# SA3_SS0_SA_UL_0_ECC_AGGR register map
Vendor: Texas Instruments
Peripheral module from a debugger description file (folder am62P).
Registers are 32-bit, access not given, reset 0x0 unless marked. A register's access mark holds for its fields unless they carry their own. Offsets are as the file gives them; lines under a group give offsets from that group; [hi:lo] are bit positions; {n}, {i} and the like mark numbered series; 'fields as' and 'values as' point back to an identical list; <NAME> marks a mode.

## SA3_SS0_SA_UL_0_ECC_AGGR
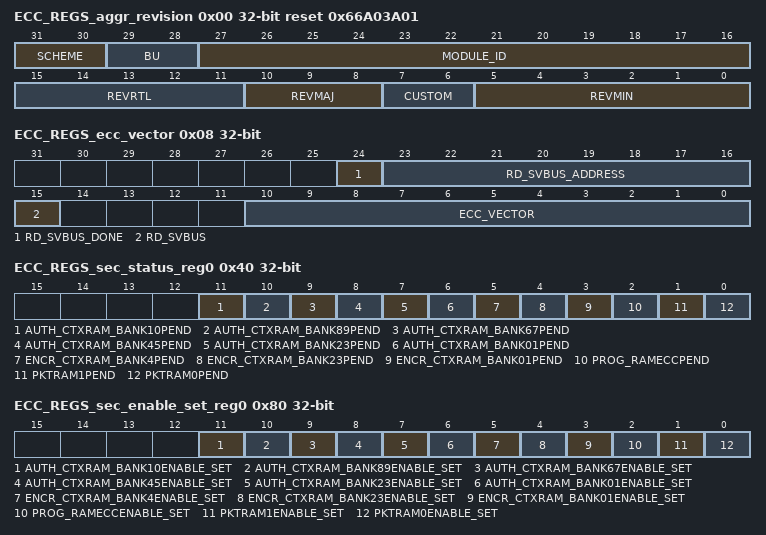
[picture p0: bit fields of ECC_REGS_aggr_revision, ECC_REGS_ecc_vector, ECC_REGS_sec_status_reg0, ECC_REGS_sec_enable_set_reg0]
0x00 ECC_REGS_aggr_revision ro reset 0x66A03A01 — Revision parameters
  [31:30] SCHEME
  [29:28] BU
  [27:16] MODULE_ID
  [15:11] REVRTL — RTL version
  [10:8] REVMAJ — Major version
  [7:6] CUSTOM — Custom version
  [5:0] REVMIN — Minor version
0x08 ECC_REGS_ecc_vector — ECC Vector Register
  [24] RD_SVBUS_DONE — Status to indicate if read on serial VBUS is complete, write of any value will clear this bit. (access R/W1TC)
  [23:16] RD_SVBUS_ADDRESS rw — Read address
  [15] RD_SVBUS — Write 1 to trigger a read on the serial VBUS (access R/W1TS)
  [10:0] ECC_VECTOR rw — Value written to select the corresponding ECC RAM for control or status
0x0C ECC_REGS_misc_status ro reset 0xC — Misc Status
  [10:0] NUM_RAMS — Indicates the number of RAMS serviced by the ECC aggregator
0x10 ECC_REGS_reserved_svbus rw — Reference other documents that contain the ECC RAM wrapper and EDC controller serial vbus register sets.
  [31:0] DATA — Serial VBUS register data
0x3C ECC_REGS_sec_eoi_reg — EOI Register
  [0] EOI_WR — EOI Register (access R/W1TS)
0x40 ECC_REGS_sec_status_reg0 — Interrupt Status Register 0
  [11] AUTH_CTXRAM_BANK10PEND — Interrupt Pending Status for auth_ctxram_bank10pend (access R/W1TS)
  [10] AUTH_CTXRAM_BANK89PEND — Interrupt Pending Status for auth_ctxram_bank89pend (access R/W1TS)
  [9] AUTH_CTXRAM_BANK67PEND — Interrupt Pending Status for auth_ctxram_bank67pend (access R/W1TS)
  [8] AUTH_CTXRAM_BANK45PEND — Interrupt Pending Status for auth_ctxram_bank45pend (access R/W1TS)
  [7] AUTH_CTXRAM_BANK23PEND — Interrupt Pending Status for auth_ctxram_bank23pend (access R/W1TS)
  [6] AUTH_CTXRAM_BANK01PEND — Interrupt Pending Status for auth_ctxram_bank01pend (access R/W1TS)
  [5] ENCR_CTXRAM_BANK4PEND — Interrupt Pending Status for encr_ctxram_bank4pend (access R/W1TS)
  [4] ENCR_CTXRAM_BANK23PEND — Interrupt Pending Status for encr_ctxram_bank23pend (access R/W1TS)
  [3] ENCR_CTXRAM_BANK01PEND — Interrupt Pending Status for encr_ctxram_bank01pend (access R/W1TS)
  [2] PROG_RAMECCPEND — Interrupt Pending Status for prog_rameccpend (access R/W1TS)
  [1] PKTRAM1PEND — Interrupt Pending Status for pktram1pend (access R/W1TS)
  [0] PKTRAM0PEND — Interrupt Pending Status for pktram0pend (access R/W1TS)
0x80 ECC_REGS_sec_enable_set_reg0 — Interrupt Enable Set Register 0
  [11] AUTH_CTXRAM_BANK10ENABLE_SET — Interrupt Enable Set Register for auth_ctxram_bank10pend (access R/W1TS)
  [10] AUTH_CTXRAM_BANK89ENABLE_SET — Interrupt Enable Set Register for auth_ctxram_bank89pend (access R/W1TS)
  [9] AUTH_CTXRAM_BANK67ENABLE_SET — Interrupt Enable Set Register for auth_ctxram_bank67pend (access R/W1TS)
  [8] AUTH_CTXRAM_BANK45ENABLE_SET — Interrupt Enable Set Register for auth_ctxram_bank45pend (access R/W1TS)
  [7] AUTH_CTXRAM_BANK23ENABLE_SET — Interrupt Enable Set Register for auth_ctxram_bank23pend (access R/W1TS)
  [6] AUTH_CTXRAM_BANK01ENABLE_SET — Interrupt Enable Set Register for auth_ctxram_bank01pend (access R/W1TS)
  [5] ENCR_CTXRAM_BANK4ENABLE_SET — Interrupt Enable Set Register for encr_ctxram_bank4pend (access R/W1TS)
  [4] ENCR_CTXRAM_BANK23ENABLE_SET — Interrupt Enable Set Register for encr_ctxram_bank23pend (access R/W1TS)
  [3] ENCR_CTXRAM_BANK01ENABLE_SET — Interrupt Enable Set Register for encr_ctxram_bank01pend (access R/W1TS)
  [2] PROG_RAMECCENABLE_SET — Interrupt Enable Set Register for prog_rameccpend (access R/W1TS)
  [1] PKTRAM1ENABLE_SET — Interrupt Enable Set Register for pktram1pend (access R/W1TS)
  [0] PKTRAM0ENABLE_SET — Interrupt Enable Set Register for pktram0pend (access R/W1TS)
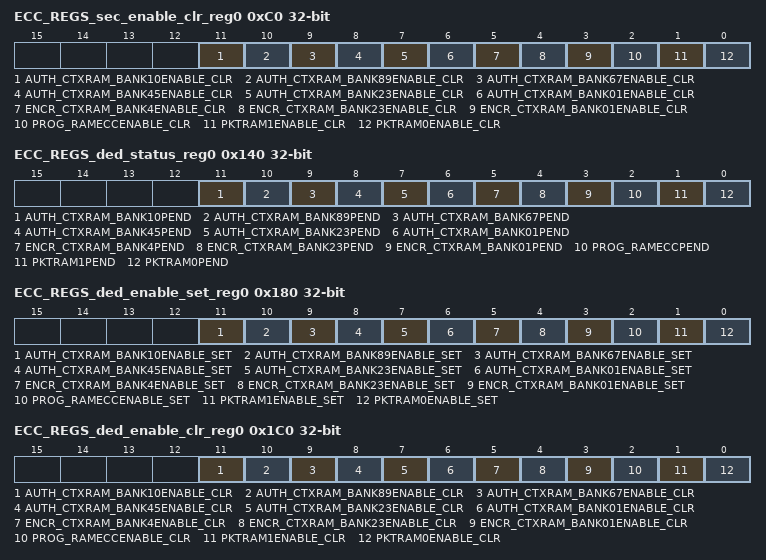
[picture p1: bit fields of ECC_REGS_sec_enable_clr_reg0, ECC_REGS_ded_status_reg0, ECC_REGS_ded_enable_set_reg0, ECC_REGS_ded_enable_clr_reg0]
0xC0 ECC_REGS_sec_enable_clr_reg0 — Interrupt Enable Clear Register 0
  [11] AUTH_CTXRAM_BANK10ENABLE_CLR — Interrupt Enable Clear Register for auth_ctxram_bank10pend (access R/W1TC)
  [10] AUTH_CTXRAM_BANK89ENABLE_CLR — Interrupt Enable Clear Register for auth_ctxram_bank89pend (access R/W1TC)
  [9] AUTH_CTXRAM_BANK67ENABLE_CLR — Interrupt Enable Clear Register for auth_ctxram_bank67pend (access R/W1TC)
  [8] AUTH_CTXRAM_BANK45ENABLE_CLR — Interrupt Enable Clear Register for auth_ctxram_bank45pend (access R/W1TC)
  [7] AUTH_CTXRAM_BANK23ENABLE_CLR — Interrupt Enable Clear Register for auth_ctxram_bank23pend (access R/W1TC)
  [6] AUTH_CTXRAM_BANK01ENABLE_CLR — Interrupt Enable Clear Register for auth_ctxram_bank01pend (access R/W1TC)
  [5] ENCR_CTXRAM_BANK4ENABLE_CLR — Interrupt Enable Clear Register for encr_ctxram_bank4pend (access R/W1TC)
  [4] ENCR_CTXRAM_BANK23ENABLE_CLR — Interrupt Enable Clear Register for encr_ctxram_bank23pend (access R/W1TC)
  [3] ENCR_CTXRAM_BANK01ENABLE_CLR — Interrupt Enable Clear Register for encr_ctxram_bank01pend (access R/W1TC)
  [2] PROG_RAMECCENABLE_CLR — Interrupt Enable Clear Register for prog_rameccpend (access R/W1TC)
  [1] PKTRAM1ENABLE_CLR — Interrupt Enable Clear Register for pktram1pend (access R/W1TC)
  [0] PKTRAM0ENABLE_CLR — Interrupt Enable Clear Register for pktram0pend (access R/W1TC)
0x13C ECC_REGS_ded_eoi_reg — EOI Register
  [0] EOI_WR — EOI Register (access R/W1TS)
0x140 ECC_REGS_ded_status_reg0 — Interrupt Status Register 0
  fields as ECC_REGS_sec_status_reg0
0x180 ECC_REGS_ded_enable_set_reg0 — Interrupt Enable Set Register 0
  fields as ECC_REGS_sec_enable_set_reg0
0x1C0 ECC_REGS_ded_enable_clr_reg0 — Interrupt Enable Clear Register 0
  fields as ECC_REGS_sec_enable_clr_reg0
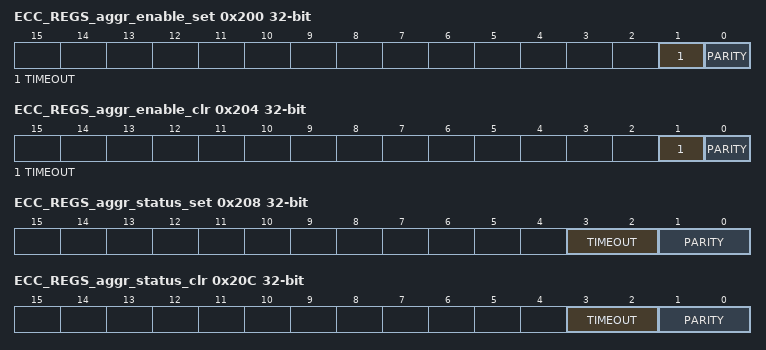
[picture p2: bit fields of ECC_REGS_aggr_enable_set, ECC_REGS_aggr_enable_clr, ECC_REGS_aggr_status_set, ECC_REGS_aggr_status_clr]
0x200 ECC_REGS_aggr_enable_set — AGGR interrupt enable set Register
  [1] TIMEOUT — interrupt enable set for svbus timeout errors (access R/W1TS)
  [0] PARITY — interrupt enable set for parity errors (access R/W1TS)
0x204 ECC_REGS_aggr_enable_clr — AGGR interrupt enable clear Register
  [1] TIMEOUT — interrupt enable clear for svbus timeout errors (access R/W1TC)
  [0] PARITY — interrupt enable clear for parity errors (access R/W1TC)
0x208 ECC_REGS_aggr_status_set — AGGR interrupt status set Register
  [3:2] TIMEOUT — interrupt status set for svbus timeout errors (access R/WI)
  [1:0] PARITY — interrupt status set for parity errors (access R/WI)
0x20C ECC_REGS_aggr_status_clr — AGGR interrupt status clear Register
  [3:2] TIMEOUT — interrupt status clear for svbus timeout errors (access R/WD)
  [1:0] PARITY — interrupt status clear for parity errors (access R/WD)
